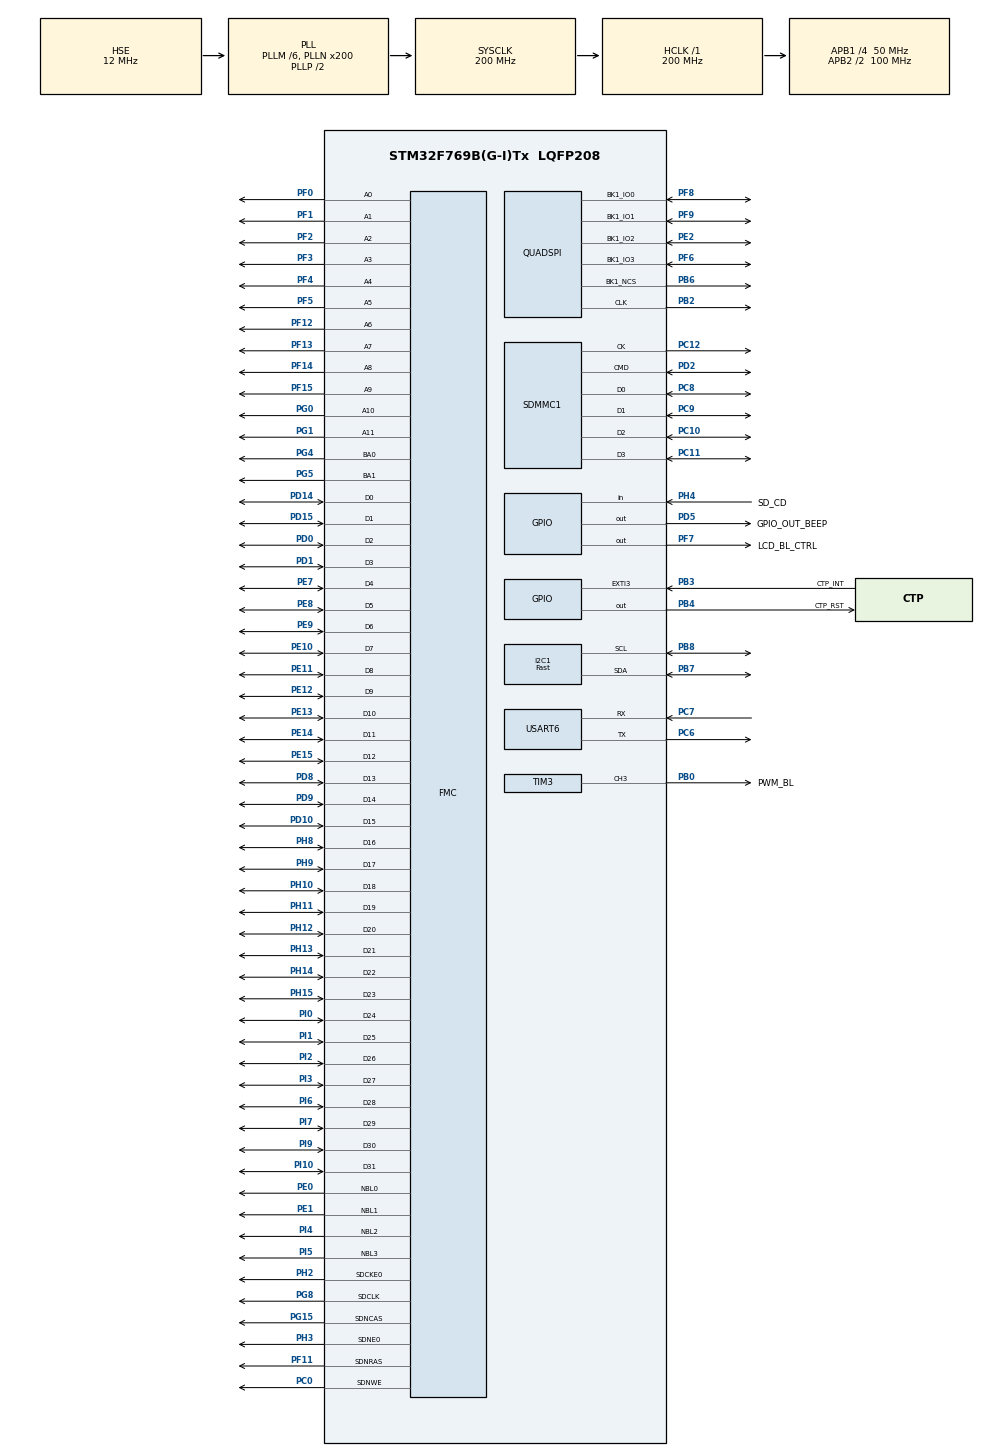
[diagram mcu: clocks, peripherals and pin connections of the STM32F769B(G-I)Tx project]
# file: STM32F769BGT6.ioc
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CORTEX_M7.ART_ACCELERATOR_ENABLE=1
CORTEX_M7.AccessPermission-Cortex_Memory_Protection_Unit_Region0_Settings=MPU_REGION_FULL_ACCESS
CORTEX_M7.AccessPermission-Cortex_Memory_Protection_Unit_Region2_Settings=MPU_REGION_PRIV_RO
CORTEX_M7.AccessPermission_S-Cortex_Memory_Protection_Unit_Region2_Settings_S=MPU_REGION_PRIV_RO
CORTEX_M7.AccessPermission_S-Cortex_Memory_Protection_Unit_Region3_Settings_S=MPU_REGION_FULL_ACCESS
CORTEX_M7.AccessPermission_Spec=MPU_REGION_FULL_ACCESS
CORTEX_M7.BaseAddress-Cortex_Memory_Protection_Unit_Region0_Settings=0xC0000000
CORTEX_M7.BaseAddress-Cortex_Memory_Protection_Unit_Region1_Settings=0x90000000
CORTEX_M7.BaseAddress-Cortex_Memory_Protection_Unit_Region2_Settings=0x90000000
CORTEX_M7.BaseAddress_S-Cortex_Memory_Protection_Unit_Region1_Settings_S=0x90000000
CORTEX_M7.BaseAddress_S-Cortex_Memory_Protection_Unit_Region2_Settings_S=0x90000000
CORTEX_M7.BaseAddress_S-Cortex_Memory_Protection_Unit_Region3_Settings_S=0xC0000000
CORTEX_M7.BaseAddress_Spec=0x20000000
CORTEX_M7.CPU_DCache=Enabled
CORTEX_M7.CPU_ICache=Enabled
CORTEX_M7.DisableExec-Cortex_Memory_Protection_Unit_Region1_Settings=MPU_INSTRUCTION_ACCESS_DISABLE
CORTEX_M7.DisableExec-Cortex_Memory_Protection_Unit_Region2_Settings=MPU_INSTRUCTION_ACCESS_DISABLE
CORTEX_M7.DisableExec_S-Cortex_Memory_Protection_Unit_Region1_Settings_S=MPU_INSTRUCTION_ACCESS_DISABLE
CORTEX_M7.DisableExec_S-Cortex_Memory_Protection_Unit_Region2_Settings_S=MPU_INSTRUCTION_ACCESS_DISABLE
CORTEX_M7.DisableExec_S-Cortex_Memory_Protection_Unit_Region3_Settings_S=MPU_INSTRUCTION_ACCESS_DISABLE
CORTEX_M7.Enable-Cortex_Memory_Protection_Unit_Region0_Settings=MPU_REGION_ENABLE
CORTEX_M7.Enable-Cortex_Memory_Protection_Unit_Region1_Settings=MPU_REGION_ENABLE
CORTEX_M7.Enable-Cortex_Memory_Protection_Unit_Region2_Settings=MPU_REGION_ENABLE
CORTEX_M7.Enable_S-Cortex_Memory_Protection_Unit_Region1_Settings_S=MPU_REGION_ENABLE
CORTEX_M7.Enable_S-Cortex_Memory_Protection_Unit_Region2_Settings_S=MPU_REGION_ENABLE
CORTEX_M7.Enable_S-Cortex_Memory_Protection_Unit_Region3_Settings_S=MPU_REGION_ENABLE
CORTEX_M7.IsBufferable_S-Cortex_Memory_Protection_Unit_Region3_Settings_S=MPU_ACCESS_BUFFERABLE
CORTEX_M7.IsBufferable_Spec=MPU_ACCESS_BUFFERABLE
CORTEX_M7.IsCacheable-Cortex_Memory_Protection_Unit_Region0_Settings=MPU_ACCESS_CACHEABLE
CORTEX_M7.IsCacheable-Cortex_Memory_Protection_Unit_Region2_Settings=MPU_ACCESS_CACHEABLE
CORTEX_M7.IsCacheable_S-Cortex_Memory_Protection_Unit_Region2_Settings_S=MPU_ACCESS_CACHEABLE
CORTEX_M7.IsCacheable_S-Cortex_Memory_Protection_Unit_Region3_Settings_S=MPU_ACCESS_CACHEABLE
CORTEX_M7.IsCacheable_Spec=MPU_ACCESS_CACHEABLE
CORTEX_M7.IsShareable-Cortex_Memory_Protection_Unit_Region0_Settings=MPU_ACCESS_SHAREABLE
CORTEX_M7.IsShareable_S-Cortex_Memory_Protection_Unit_Region3_Settings_S=MPU_ACCESS_NOT_SHAREABLE
CORTEX_M7.IsShareable_Spec=MPU_ACCESS_NOT_SHAREABLE
CORTEX_M7.MPU_Control=MPU_PRIVILEGED_DEFAULT
CORTEX_M7.Size-Cortex_Memory_Protection_Unit_Region0_Settings=MPU_REGION_SIZE_16MB
CORTEX_M7.Size-Cortex_Memory_Protection_Unit_Region1_Settings=MPU_REGION_SIZE_256MB
CORTEX_M7.Size-Cortex_Memory_Protection_Unit_Region2_Settings=MPU_REGION_SIZE_16MB
CORTEX_M7.Size_S-Cortex_Memory_Protection_Unit_Region1_Settings_S=MPU_REGION_SIZE_256MB
CORTEX_M7.Size_S-Cortex_Memory_Protection_Unit_Region2_Settings_S=MPU_REGION_SIZE_16MB
CORTEX_M7.Size_S-Cortex_Memory_Protection_Unit_Region3_Settings_S=MPU_REGION_SIZE_16MB
CORTEX_M7.Size_Spec=MPU_REGION_SIZE_512KB
CORTEX_M7.SubRegionDisable_Spec=0
CORTEX_M7.default_mode_Activation=0
DMA2D.ColorMode=DMA2D_OUTPUT_RGB565
DSIHOST.BTA_FlowControl=__NULL
DSIHOST.FrameBTAAcknowledgeEnable=DSI_FBTAA_ENABLE
DSIHOST.GCEIE=HAL_DSI_ERROR_NONE
DSIHOST.LPCommandEnable=DSI_LP_COMMAND_ENABLE
DSIHOST.LPHorizontalBackPorchEnable=DSI_LP_HBP_ENABLE
DSIHOST.LPHorizontalFrontPorchEnable=DSI_LP_HFP_ENABLE
DSIHOST.LPLargestPacketSize=16
DSIHOST.LPVACTLargestPacketSize=0
DSIHOST.LPVerticalActiveEnable=DSI_LP_VACT_ENABLE
DSIHOST.LPVerticalBackPorchEnable=DSI_LP_VBP_ENABLE
DSIHOST.LPVerticalFrontPorchEnable=DSI_LP_VFP_ENABLE
DSIHOST.LPVerticalSyncActiveEnable=DSI_LP_VSYNC_ENABLE
DSIHOST.LPWREIE=HAL_DSI_ERROR_OVF
DSIHOST.Mode=DSI_VID_MODE_BURST
DSIHOST.NumberOfLanes=DSI_TWO_DATA_LANES
DSIHOST.State_SDD=__NULL
DSIHOST.StopWaitTime=0
DSIHOST_CKN.Mode=DSIHost_Video
DSIHOST_CKN.Signal=DSIHOST_CKN
DSIHOST_CKP.Mode=DSIHost_Video
DSIHOST_CKP.Signal=DSIHOST_CKP
DSIHOST_D0N.Mode=DSIHost_Video
DSIHOST_D0N.Signal=DSIHOST_D0N
DSIHOST_D0P.Mode=DSIHost_Video
DSIHOST_D0P.Signal=DSIHOST_D0P
DSIHOST_D1N.Mode=DSIHost_Video
DSIHOST_D1N.Signal=DSIHOST_D1N
DSIHOST_D1P.Mode=DSIHost_Video
DSIHOST_D1P.Signal=DSIHOST_D1P
Dma.Request0=SDMMC1_RX
Dma.Request1=SDMMC1_TX
Dma.SDMMC1_RX.0.Direction=DMA_PERIPH_TO_MEMORY
Dma.SDMMC1_RX.0.FIFOMode=DMA_FIFOMODE_ENABLE
Dma.SDMMC1_RX.0.FIFOThreshold=DMA_FIFO_THRESHOLD_FULL
Dma.SDMMC1_RX.0.Instance=DMA2_Stream3
Dma.SDMMC1_RX.0.MemBurst=DMA_MBURST_INC4
Dma.SDMMC1_RX.0.MemDataAlignment=DMA_MDATAALIGN_WORD
Dma.SDMMC1_RX.0.MemInc=DMA_MINC_ENABLE
Dma.SDMMC1_RX.0.Mode=DMA_PFCTRL
Dma.SDMMC1_RX.0.PeriphBurst=DMA_PBURST_INC4
Dma.SDMMC1_RX.0.PeriphDataAlignment=DMA_PDATAALIGN_WORD
Dma.SDMMC1_RX.0.PeriphInc=DMA_PINC_DISABLE
Dma.SDMMC1_RX.0.Priority=DMA_PRIORITY_LOW
Dma.SDMMC1_TX.1.Direction=DMA_MEMORY_TO_PERIPH
Dma.SDMMC1_TX.1.FIFOMode=DMA_FIFOMODE_ENABLE
Dma.SDMMC1_TX.1.FIFOThreshold=DMA_FIFO_THRESHOLD_FULL
Dma.SDMMC1_TX.1.Instance=DMA2_Stream6
Dma.SDMMC1_TX.1.MemBurst=DMA_MBURST_INC4
Dma.SDMMC1_TX.1.MemDataAlignment=DMA_MDATAALIGN_WORD
Dma.SDMMC1_TX.1.MemInc=DMA_MINC_ENABLE
Dma.SDMMC1_TX.1.Mode=DMA_PFCTRL
Dma.SDMMC1_TX.1.PeriphBurst=DMA_PBURST_INC4
Dma.SDMMC1_TX.1.PeriphDataAlignment=DMA_PDATAALIGN_WORD
Dma.SDMMC1_TX.1.PeriphInc=DMA_PINC_DISABLE
Dma.SDMMC1_TX.1.Priority=DMA_PRIORITY_LOW
FATFS.BSP.number=1
FATFS._CODE_PAGE=950
FATFS._FS_EXFAT=1
FATFS._USE_LFN=2
FATFS0.BSP.STBoard=false
FATFS0.BSP.api=Unknown
FATFS0.BSP.instance=PH4
FATFS0.BSP.ip=GPIO
FATFS0.BSP.mode=Input
FATFS0.BSP.name=Detect_SDIO
FATFS0.BSP.solution=PH4
FMC.CASLatency1=FMC_SDRAM_CAS_LATENCY_2
FMC.ExitSelfRefreshDelay1=8
FMC.LoadToActiveDelay1=2
FMC.RCDDelay1=2
FMC.RPDelay1=2
FMC.ReadBurst1=FMC_SDRAM_RBURST_ENABLE
FMC.RowCycleDelay1=6
FMC.RowCycleDelay2=6
FMC.SDClockPeriod1=FMC_SDRAM_CLOCK_PERIOD_2
FMC.SelfRefreshTime1=5
FMC.WriteRecoveryTime1=4
FREERTOS.Tasks01=display_debug,24,500,display_debugTask,Default,NULL,Dynamic,NULL,NULL;TouchgfxTask,24,4096,StartTouchgfxTask,Default,NULL,Dynamic,NULL,NULL
FREERTOS.configENABLE_FPU=1
FREERTOS.configTOTAL_HEAP_SIZE=80000
FREERTOS.configUSE_IDLE_HOOK=1
FREERTOS.configUSE_NEWLIB_REENTRANT=1
I2C1.I2C_Speed_Mode=I2C_Fast
I2C1.Timing=0x109035B7
LTDC.ActiveH=1424
LTDC.ActiveW=280
LTDC.Alpha_L0=255
LTDC.BlendingFactor1_L0=LTDC_BLENDING_FACTOR1_CA
LTDC.BlendingFactor2_L0=LTDC_BLENDING_FACTOR2_CA
LTDC.Blue_L0=255
LTDC.FBStartAdress_L0=0xC0000000
LTDC.Green_L0=255
LTDC.HBP=40
LTDC.HFP=150
LTDC.HSync=24
LTDC.ImageHeight_L0=1424
LTDC.ImageWidth_L0=280
LTDC.Layers=0
LTDC.PixelFormat_L0=LTDC_PIXEL_FORMAT_RGB565
LTDC.Red_L0=255
LTDC.VBP=10
LTDC.VFP=12
LTDC.VSync=6
LTDC.WindowX1_L0=280
LTDC.WindowY1_L0=1424
Mcu.Family=STM32F7
Mcu.Name=STM32F769B(G-I)Tx
Mcu.Package=LQFP208
NVIC.DMA2D_IRQn=true\:5\:0\:false\:false\:true\:true\:true\:true\:true
NVIC.DMA2_Stream3_IRQn=true\:5\:0\:false\:false\:true\:true\:false\:true\:true
NVIC.DMA2_Stream6_IRQn=true\:5\:0\:false\:false\:true\:true\:false\:true\:true
NVIC.EXTI3_IRQn=true\:5\:0\:false\:false\:true\:true\:true\:true\:true
NVIC.I2C1_ER_IRQn=true\:5\:0\:false\:false\:true\:true\:true\:true\:true
NVIC.I2C1_EV_IRQn=true\:5\:0\:false\:false\:true\:true\:true\:true\:true
NVIC.LTDC_IRQn=true\:5\:0\:false\:false\:true\:true\:true\:true\:true
NVIC.PriorityGroup=NVIC_PRIORITYGROUP_4
NVIC.SDMMC1_IRQn=true\:5\:0\:false\:false\:true\:true\:true\:true\:true
NVIC.TIM6_DAC_IRQn=true\:0\:0\:true\:false\:true\:false\:false\:true\:true
NVIC.TimeBase=TIM6_DAC_IRQn
NVIC.TimeBaseIP=TIM6
NVIC.USART6_IRQn=true\:5\:0\:false\:false\:true\:true\:true\:true\:true
PA13.Mode=Serial_Wire
PA13.Signal=SYS_JTMS-SWDIO
PA14.Mode=Serial_Wire
PA14.Signal=SYS_JTCK-SWCLK
PB0.GPIO_Label=PWM_BL
PB0.Signal=S_TIM3_CH3
PB2.Mode=Single Bank 1
PB2.Signal=QUADSPI_CLK
PB3.GPIO_Label=CTP_INT
PB3.GPIO_ModeDefaultEXTI=GPIO_MODE_IT_FALLING
PB3.Signal=GPXTI3
PB4.GPIO_Label=CTP_RST
PB4.Signal=GPIO_Output
PB6.Mode=Single Bank 1
PB6.Signal=QUADSPI_BK1_NCS
PB7.GPIO_Pu=GPIO_PULLUP
PB7.Mode=I2C
PB7.Signal=I2C1_SDA
PB8.GPIO_Pu=GPIO_PULLUP
PB8.Mode=I2C
PB8.Signal=I2C1_SCL
PC0.Signal=FMC_SDNWE
PC10.Mode=SD_4_bits_Wide_bus
PC10.Signal=SDMMC1_D2
PC11.Mode=SD_4_bits_Wide_bus
PC11.Signal=SDMMC1_D3
PC12.Mode=SD_4_bits_Wide_bus
PC12.Signal=SDMMC1_CK
PC14/OSC32_IN.Mode=LSE-External-Oscillator
PC14/OSC32_IN.Signal=RCC_OSC32_IN
PC15/OSC32_OUT.Mode=LSE-External-Oscillator
PC15/OSC32_OUT.Signal=RCC_OSC32_OUT
PC6.Mode=Asynchronous
PC6.Signal=USART6_TX
PC7.Mode=Asynchronous
PC7.Signal=USART6_RX
PC8.Mode=SD_4_bits_Wide_bus
PC8.Signal=SDMMC1_D0
PC9.Mode=SD_4_bits_Wide_bus
PC9.Signal=SDMMC1_D1
PD0.Signal=FMC_D2_DA2
PD1.Signal=FMC_D3_DA3
PD10.Signal=FMC_D15_DA15
PD14.Signal=FMC_D0_DA0
PD15.Signal=FMC_D1_DA1
PD2.Mode=SD_4_bits_Wide_bus
PD2.Signal=SDMMC1_CMD
PD5.GPIO_Label=GPIO_OUT_BEEP
PD5.GPIO_Speed=GPIO_SPEED_FREQ_VERY_HIGH
PD5.Signal=GPIO_Output
PD8.Signal=FMC_D13_DA13
PD9.Signal=FMC_D14_DA14
PE0.Signal=FMC_NBL0
PE1.Signal=FMC_NBL1
PE10.Signal=FMC_D7_DA7
PE11.Signal=FMC_D8_DA8
PE12.Signal=FMC_D9_DA9
PE13.Signal=FMC_D10_DA10
PE14.Signal=FMC_D11_DA11
PE15.Signal=FMC_D12_DA12
PE2.Mode=Single Bank 1
PE2.Signal=QUADSPI_BK1_IO2
PE7.Signal=FMC_D4_DA4
PE8.Signal=FMC_D5_DA5
PE9.Signal=FMC_D6_DA6
PF0.Signal=FMC_A0
PF1.Signal=FMC_A1
PF11.Signal=FMC_SDNRAS
PF12.Signal=FMC_A6
PF13.Signal=FMC_A7
PF14.Signal=FMC_A8
PF15.Signal=FMC_A9
PF2.Signal=FMC_A2
PF3.Signal=FMC_A3
PF4.Signal=FMC_A4
PF5.Signal=FMC_A5
PF6.Mode=Single Bank 1
PF6.Signal=QUADSPI_BK1_IO3
PF7.GPIO_Label=LCD_BL_CTRL
PF7.GPIO_Speed=GPIO_SPEED_FREQ_VERY_HIGH
PF7.Signal=GPIO_Output
PF8.Mode=Single Bank 1
PF8.Signal=QUADSPI_BK1_IO0
PF9.Mode=Single Bank 1
PF9.Signal=QUADSPI_BK1_IO1
PG0.Signal=FMC_A10
PG1.Signal=FMC_A11
PG15.Signal=FMC_SDNCAS
PG4.Signal=FMC_A14_BA0
PG5.Signal=FMC_A15_BA1
PG8.Signal=FMC_SDCLK
PH0/OSC_IN.Mode=HSE-External-Oscillator
PH0/OSC_IN.Signal=RCC_OSC_IN
PH1/OSC_OUT.Mode=HSE-External-Oscillator
PH1/OSC_OUT.Signal=RCC_OSC_OUT
PH10.Signal=FMC_D18
PH11.Signal=FMC_D19
PH12.Signal=FMC_D20
PH13.Signal=FMC_D21
PH14.Signal=FMC_D22
PH15.Signal=FMC_D23
PH2.Mode=SdramChipSelect1_1
PH2.Signal=FMC_SDCKE0
PH3.Mode=SdramChipSelect1_1
PH3.Signal=FMC_SDNE0
PH4.GPIO_Label=SD_CD
PH4.Signal=GPIO_Input
PH8.Signal=FMC_D16
PH9.Signal=FMC_D17
PI0.Signal=FMC_D24
PI1.Signal=FMC_D25
PI10.Signal=FMC_D31
PI2.Signal=FMC_D26
PI3.Signal=FMC_D27
PI4.Signal=FMC_NBL2
PI5.Signal=FMC_NBL3
PI6.Signal=FMC_D28
PI7.Signal=FMC_D29
PI9.Signal=FMC_D30
ProjectManager.HeapSize=0x1000
ProjectManager.StackSize=0x1000
ProjectManager.TargetToolchain=STM32CubeIDE
QUADSPI.ChipSelectHighTime=QSPI_CS_HIGH_TIME_2_CYCLE
QUADSPI.ClockPrescaler=2
QUADSPI.FifoThreshold=4
QUADSPI.FlashSize=23
QUADSPI.SampleShifting=QSPI_SAMPLE_SHIFTING_HALFCYCLE
RCC.AHBFreq_Value=200000000
RCC.APB1CLKDivider=RCC_HCLK_DIV4
RCC.APB1Freq_Value=50000000
RCC.APB1TimFreq_Value=100000000
RCC.APB2CLKDivider=RCC_HCLK_DIV2
RCC.APB2Freq_Value=100000000
RCC.APB2TimFreq_Value=200000000
RCC.CortexFreq_Value=200000000
RCC.HCLKFreq_Value=200000000
RCC.HSE_VALUE=12000000
RCC.HSI_VALUE=16000000
RCC.I2C1CLockSelection=RCC_I2C1CLKSOURCE_SYSCLK
RCC.LSE_Drive_Capability=RCC_LSEDRIVE_HIGH
RCC.PLLDSIIDF=DSI_PLL_IN_DIV3
RCC.PLLDSINDIV=125
RCC.PLLM=6
RCC.PLLN=200
RCC.PLLQ=8
RCC.PLLR=7
RCC.PLLSAIN=120
RCC.PLLSAIR=3
RCC.PLLSourceVirtual=RCC_PLLSOURCE_HSE
RCC.PWR_Regulator_Voltage_Scale=PWR_REGULATOR_VOLTAGE_SCALE1
RCC.RTCClockSelection=RCC_RTCCLKSOURCE_LSE
RCC.SDMMCClockSelection=RCC_SDMMC1CLKSOURCE_CLK48
RCC.SYSCLKFreq_VALUE=200000000
RCC.SYSCLKSource=RCC_SYSCLKSOURCE_PLLCLK
RCC.USART6CLockSelection=RCC_USART6CLKSOURCE_SYSCLK
RCC.USBFreq_Value=50000000
RCC.VCOOutputFreq_Value=400000000
RTC.Format=RTC_FORMAT_BIN
RTC.Year=24
SH.FMC_A0.0=FMC_A0,12b-sda1
SH.FMC_A1.0=FMC_A1,12b-sda1
SH.FMC_A10.0=FMC_A10,12b-sda1
SH.FMC_A11.0=FMC_A11,12b-sda1
SH.FMC_A14_BA0.0=FMC_BA0,FourSdramBanks1
SH.FMC_A15_BA1.0=FMC_BA1,FourSdramBanks1
SH.FMC_A2.0=FMC_A2,12b-sda1
SH.FMC_A3.0=FMC_A3,12b-sda1
SH.FMC_A4.0=FMC_A4,12b-sda1
SH.FMC_A5.0=FMC_A5,12b-sda1
SH.FMC_A6.0=FMC_A6,12b-sda1
SH.FMC_A7.0=FMC_A7,12b-sda1
SH.FMC_A8.0=FMC_A8,12b-sda1
SH.FMC_A9.0=FMC_A9,12b-sda1
SH.FMC_D0_DA0.0=FMC_D0,sd-32b-d1
SH.FMC_D10_DA10.0=FMC_D10,sd-32b-d1
SH.FMC_D11_DA11.0=FMC_D11,sd-32b-d1
SH.FMC_D12_DA12.0=FMC_D12,sd-32b-d1
SH.FMC_D13_DA13.0=FMC_D13,sd-32b-d1
SH.FMC_D14_DA14.0=FMC_D14,sd-32b-d1
SH.FMC_D15_DA15.0=FMC_D15,sd-32b-d1
SH.FMC_D16.0=FMC_D16,sd-32b-d1
SH.FMC_D17.0=FMC_D17,sd-32b-d1
SH.FMC_D18.0=FMC_D18,sd-32b-d1
SH.FMC_D19.0=FMC_D19,sd-32b-d1
SH.FMC_D1_DA1.0=FMC_D1,sd-32b-d1
SH.FMC_D20.0=FMC_D20,sd-32b-d1
SH.FMC_D21.0=FMC_D21,sd-32b-d1
SH.FMC_D22.0=FMC_D22,sd-32b-d1
SH.FMC_D23.0=FMC_D23,sd-32b-d1
SH.FMC_D24.0=FMC_D24,sd-32b-d1
SH.FMC_D25.0=FMC_D25,sd-32b-d1
SH.FMC_D26.0=FMC_D26,sd-32b-d1
SH.FMC_D27.0=FMC_D27,sd-32b-d1
SH.FMC_D28.0=FMC_D28,sd-32b-d1
SH.FMC_D29.0=FMC_D29,sd-32b-d1
SH.FMC_D2_DA2.0=FMC_D2,sd-32b-d1
SH.FMC_D30.0=FMC_D30,sd-32b-d1
SH.FMC_D31.0=FMC_D31,sd-32b-d1
SH.FMC_D3_DA3.0=FMC_D3,sd-32b-d1
SH.FMC_D4_DA4.0=FMC_D4,sd-32b-d1
SH.FMC_D5_DA5.0=FMC_D5,sd-32b-d1
SH.FMC_D6_DA6.0=FMC_D6,sd-32b-d1
SH.FMC_D7_DA7.0=FMC_D7,sd-32b-d1
SH.FMC_D8_DA8.0=FMC_D8,sd-32b-d1
SH.FMC_D9_DA9.0=FMC_D9,sd-32b-d1
SH.FMC_NBL0.0=FMC_NBL0,Sd4ByteEnable1
SH.FMC_NBL1.0=FMC_NBL1,Sd4ByteEnable1
SH.FMC_NBL2.0=FMC_NBL2,Sd4ByteEnable1
SH.FMC_NBL3.0=FMC_NBL3,Sd4ByteEnable1
SH.FMC_SDCLK.0=FMC_SDCLK,12b-sda1
SH.FMC_SDNCAS.0=FMC_SDNCAS,12b-sda1
SH.FMC_SDNRAS.0=FMC_SDNRAS,12b-sda1
SH.FMC_SDNWE.0=FMC_SDNWE,12b-sda1
SH.S_TIM3_CH3.0=TIM3_CH3,PWM Generation3 CH3
STMicroelectronics.X-CUBE-TOUCHGFX.4.18.1.ApplicationCcGraphicsJjApplication=TouchGFXOoGenerator
STMicroelectronics.X-CUBE-TOUCHGFX.4.18.1.tgfx_buffering_strategy=Double
STMicroelectronics.X-CUBE-TOUCHGFX.4.18.1.tgfx_custom_height=1424
STMicroelectronics.X-CUBE-TOUCHGFX.4.18.1.tgfx_display_interface=disp_ltdc
STMicroelectronics.X-CUBE-TOUCHGFX.4.18.1.tgfx_hardware_accelerator=dma_2d
STMicroelectronics.X-CUBE-TOUCHGFX.4.18.1.tgfx_pixel_format=RGB565\:16
STMicroelectronics.X-CUBE-TOUCHGFX.4.18.1.tgfx_vsync=vsync_ltdc
STMicroelectronics.X-CUBE-TOUCHGFX.4.18.1_IsPackSelfContextualization=true
TIM3.Channel-PWM\ Generation3\ CH3=TIM_CHANNEL_3
TIM3.OCPolarity_3=TIM_OCPOLARITY_LOW
TIM3.Period=100-1
TIM3.Prescaler=100-1
USART6.VirtualMode-Asynchronous=VM_ASYNC
VP_CRC_VS_CRC.Mode=CRC_Activate
VP_DMA2D_VS_DMA2D.Mode=DMA2D_Activate
VP_FATFS_VS_SDIO.Mode=SDIO
VP_FREERTOS_VS_CMSIS_V2.Mode=CMSIS_V2
VP_LTDC_DSIMode.Mode=RGB565
VP_RTC_VS_RTC_Activate.Mode=RTC_Enabled
VP_RTC_VS_RTC_Calendar.Mode=RTC_Calendar
VP_STMicroelectronics.X-CUBE-TOUCHGFX_VS_GraphicsJjApplication_4.18.1.Mode=GraphicsJjApplication
VP_SYS_VS_tim6.Mode=TIM6
VP_TIM3_VS_ClockSourceINT.Mode=Internal
board=custom

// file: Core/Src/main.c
/* USER CODE BEGIN Header */
/**
  ******************************************************************************
  * @file           : main.c
  * @brief          : Main program body
  ******************************************************************************
  * @attention
  *
  * Copyright (c) 2024 STMicroelectronics.
  * All rights reserved.
  *
  * This software is licensed under terms that can be found in the LICENSE file
  * in the root directory of this software component.
  * If no LICENSE file comes with this software, it is provided AS-IS.
  *
  ******************************************************************************
  */
/* USER CODE END Header */
#include "main.h"
#include "cmsis_os.h"
#include "fatfs.h"
#include "app_touchgfx.h"

/* USER CODE BEGIN Includes */
#include <string.h>
#include <ExFlash.h>
#include <ota7290n.h>
#include "ExHardware.h"
/* USER CODE END Includes */

/* USER CODE BEGIN PM */
#define LAYER0_ADDRESS               ((uint32_t)0xC0000000)

extern uint8_t pucByte;

Touch_t Touch;
/* USER CODE END PM */

CRC_HandleTypeDef hcrc;

DMA2D_HandleTypeDef hdma2d;

DSI_HandleTypeDef hdsi;

I2C_HandleTypeDef hi2c1;

LTDC_HandleTypeDef hltdc;

QSPI_HandleTypeDef hqspi;

RTC_HandleTypeDef hrtc;

SD_HandleTypeDef hsd1;
DMA_HandleTypeDef hdma_sdmmc1_rx;
DMA_HandleTypeDef hdma_sdmmc1_tx;

TIM_HandleTypeDef htim3;

UART_HandleTypeDef huart6;

SDRAM_HandleTypeDef hsdram1;

/* Definitions for display_debug */
osThreadId_t display_debugHandle;
const osThreadAttr_t display_debug_attributes = {
  .name = "display_debug",
  .stack_size = 500 * 4,
  .priority = (osPriority_t) osPriorityNormal,
};
/* Definitions for TouchgfxTask */
osThreadId_t TouchgfxTaskHandle;
const osThreadAttr_t TouchgfxTask_attributes = {
  .name = "TouchgfxTask",
  .stack_size = 4096 * 4,
  .priority = (osPriority_t) osPriorityNormal,
};

void SystemClock_Config(void);
static void MPU_Config(void);
static void MX_GPIO_Init(void);
static void MX_DMA2D_Init(void);
static void MX_FMC_Init(void);
static void MX_LTDC_Init(void);
static void MX_QUADSPI_Init(void);
static void MX_CRC_Init(void);
static void MX_DSIHOST_DSI_Init(void);
static void MX_TIM3_Init(void);
static void MX_I2C1_Init(void);
static void MX_SDMMC1_SD_Init(void);
static void MX_DMA_Init(void);
static void MX_USART6_UART_Init(void);
static void MX_RTC_Init(void);
void display_debugTask(void *argument);
void StartTouchgfxTask(void *argument);

/* USER CODE BEGIN PFP */
static void MX_SDRAM_InitEx ( void );
/* USER CODE END PFP */

int main(void)
{

  /* MPU Configuration--------------------------------------------------------*/
  MPU_Config();

  /* Enable I-Cache---------------------------------------------------------*/
  SCB_EnableICache();

  /* Enable D-Cache---------------------------------------------------------*/
  SCB_EnableDCache();

  /* MCU Configuration--------------------------------------------------------*/

  /* Reset of all peripherals, Initializes the Flash interface and the Systick. */
  HAL_Init();

  /* Configure the system clock */
  SystemClock_Config();

  /* Initialize all configured peripherals */
  MX_GPIO_Init();
  MX_DMA2D_Init();
  MX_FMC_Init();
  MX_LTDC_Init();
  MX_QUADSPI_Init();
  MX_CRC_Init();
  MX_DSIHOST_DSI_Init();
  MX_TIM3_Init();
  MX_I2C1_Init();
  MX_SDMMC1_SD_Init();
  MX_DMA_Init();
  MX_FATFS_Init();
  MX_USART6_UART_Init();
  MX_RTC_Init();
  MX_TouchGFX_Init();
  /* USER CODE BEGIN 2 */
  HAL_DSI_Start(&hdsi);

  OTA7290N_Init();

  memset((void *)0xC0000000, 0x00, 280*1424*2*2); //RESET

  HAL_LTDC_ProgramLineEvent(&hltdc, 0);

  HAL_UART_Receive_IT(&huart6, &pucByte, 1);

  HAL_GPIO_WritePin( GPIO_OUT_BEEP_GPIO_Port, GPIO_OUT_BEEP_Pin, GPIO_PIN_SET );
  HAL_Delay(100);
  HAL_GPIO_WritePin( GPIO_OUT_BEEP_GPIO_Port, GPIO_OUT_BEEP_Pin, GPIO_PIN_RESET );

  /* USER CODE END 2 */

  /* Init scheduler */
  osKernelInitialize();

  /* Create the thread(s) */
  /* creation of display_debug */
  display_debugHandle = osThreadNew(display_debugTask, NULL, &display_debug_attributes);

  /* creation of TouchgfxTask */
  TouchgfxTaskHandle = osThreadNew(StartTouchgfxTask, NULL, &TouchgfxTask_attributes);

  /* Start scheduler */
  osKernelStart();

  /* We should never get here as control is now taken by the scheduler */
  /* Infinite loop */
  while (1)
  {

  }
}

void SystemClock_Config(void)
{
  RCC_OscInitTypeDef RCC_OscInitStruct = {0};
  RCC_ClkInitTypeDef RCC_ClkInitStruct = {0};

  /** Configure LSE Drive Capability
  */
  HAL_PWR_EnableBkUpAccess();
  __HAL_RCC_LSEDRIVE_CONFIG(RCC_LSEDRIVE_HIGH);

  /** Configure the main internal regulator output voltage
  */
  __HAL_RCC_PWR_CLK_ENABLE();
  __HAL_PWR_VOLTAGESCALING_CONFIG(PWR_REGULATOR_VOLTAGE_SCALE1);

  /** Initializes the RCC Oscillators according to the specified parameters
  * in the RCC_OscInitTypeDef structure.
  */
  RCC_OscInitStruct.OscillatorType = RCC_OSCILLATORTYPE_HSE|RCC_OSCILLATORTYPE_LSE;
  RCC_OscInitStruct.HSEState = RCC_HSE_ON;
  RCC_OscInitStruct.LSEState = RCC_LSE_ON;
  RCC_OscInitStruct.PLL.PLLState = RCC_PLL_ON;
  RCC_OscInitStruct.PLL.PLLSource = RCC_PLLSOURCE_HSE;
  RCC_OscInitStruct.PLL.PLLM = 6;
  RCC_OscInitStruct.PLL.PLLN = 200;
  RCC_OscInitStruct.PLL.PLLP = RCC_PLLP_DIV2;
  RCC_OscInitStruct.PLL.PLLQ = 8;
  RCC_OscInitStruct.PLL.PLLR = 7;
  if (HAL_RCC_OscConfig(&RCC_OscInitStruct) != HAL_OK)
  {
    Error_Handler();
  }

  /** Activate the Over-Drive mode
  */
  if (HAL_PWREx_EnableOverDrive() != HAL_OK)
  {
    Error_Handler();
  }

  /** Initializes the CPU, AHB and APB buses clocks
  */
  RCC_ClkInitStruct.ClockType = RCC_CLOCKTYPE_HCLK|RCC_CLOCKTYPE_SYSCLK
                              |RCC_CLOCKTYPE_PCLK1|RCC_CLOCKTYPE_PCLK2;
  RCC_ClkInitStruct.SYSCLKSource = RCC_SYSCLKSOURCE_PLLCLK;
  RCC_ClkInitStruct.AHBCLKDivider = RCC_SYSCLK_DIV1;
  RCC_ClkInitStruct.APB1CLKDivider = RCC_HCLK_DIV4;
  RCC_ClkInitStruct.APB2CLKDivider = RCC_HCLK_DIV2;

  if (HAL_RCC_ClockConfig(&RCC_ClkInitStruct, FLASH_LATENCY_6) != HAL_OK)
  {
    Error_Handler();
  }
}

static void MX_CRC_Init(void)
{

  hcrc.Instance = CRC;
  hcrc.Init.DefaultPolynomialUse = DEFAULT_POLYNOMIAL_ENABLE;
  hcrc.Init.DefaultInitValueUse = DEFAULT_INIT_VALUE_ENABLE;
  hcrc.Init.InputDataInversionMode = CRC_INPUTDATA_INVERSION_NONE;
  hcrc.Init.OutputDataInversionMode = CRC_OUTPUTDATA_INVERSION_DISABLE;
  hcrc.InputDataFormat = CRC_INPUTDATA_FORMAT_BYTES;
  if (HAL_CRC_Init(&hcrc) != HAL_OK)
  {
    Error_Handler();
  }

}

static void MX_DMA2D_Init(void)
{

  hdma2d.Instance = DMA2D;
  hdma2d.Init.Mode = DMA2D_M2M;
  hdma2d.Init.ColorMode = DMA2D_OUTPUT_RGB565;
  hdma2d.Init.OutputOffset = 0;
  hdma2d.LayerCfg[1].InputOffset = 0;
  hdma2d.LayerCfg[1].InputColorMode = DMA2D_INPUT_RGB565;
  hdma2d.LayerCfg[1].AlphaMode = DMA2D_NO_MODIF_ALPHA;
  hdma2d.LayerCfg[1].InputAlpha = 0;
  hdma2d.LayerCfg[1].AlphaInverted = DMA2D_REGULAR_ALPHA;
  hdma2d.LayerCfg[1].RedBlueSwap = DMA2D_RB_REGULAR;
  if (HAL_DMA2D_Init(&hdma2d) != HAL_OK)
  {
    Error_Handler();
  }
  if (HAL_DMA2D_ConfigLayer(&hdma2d, 1) != HAL_OK)
  {
    Error_Handler();
  }

}

static void MX_DSIHOST_DSI_Init(void)
{

  DSI_PLLInitTypeDef PLLInit = {0};
  DSI_HOST_TimeoutTypeDef HostTimeouts = {0};
  DSI_PHY_TimerTypeDef PhyTimings = {0};
  DSI_VidCfgTypeDef VidCfg = {0};

  /* USER CODE BEGIN DSIHOST_Init 1 */
  hdsi.Instance = DSI;

  HAL_DSI_DeInit( &hdsi );

  /* USER CODE END DSIHOST_Init 1 */
  hdsi.Instance = DSI;
  hdsi.Init.AutomaticClockLaneControl = DSI_AUTO_CLK_LANE_CTRL_DISABLE;
  hdsi.Init.TXEscapeCkdiv = 4;
  hdsi.Init.NumberOfLanes = DSI_TWO_DATA_LANES;
  PLLInit.PLLNDIV = 125;
  PLLInit.PLLIDF = DSI_PLL_IN_DIV3;
  PLLInit.PLLODF = DSI_PLL_OUT_DIV1;
  if (HAL_DSI_Init(&hdsi, &PLLInit) != HAL_OK)
  {
    Error_Handler();
  }
  HostTimeouts.TimeoutCkdiv = 1;
  HostTimeouts.HighSpeedTransmissionTimeout = 0;
  HostTimeouts.LowPowerReceptionTimeout = 0;
  HostTimeouts.HighSpeedReadTimeout = 0;
  HostTimeouts.LowPowerReadTimeout = 0;
  HostTimeouts.HighSpeedWriteTimeout = 0;
  HostTimeouts.HighSpeedWritePrespMode = DSI_HS_PM_DISABLE;
  HostTimeouts.LowPowerWriteTimeout = 0;
  HostTimeouts.BTATimeout = 0;
  if (HAL_DSI_ConfigHostTimeouts(&hdsi, &HostTimeouts) != HAL_OK)
  {
    Error_Handler();
  }
  PhyTimings.ClockLaneHS2LPTime = 28;
  PhyTimings.ClockLaneLP2HSTime = 33;
  PhyTimings.DataLaneHS2LPTime = 15;
  PhyTimings.DataLaneLP2HSTime = 25;
  PhyTimings.DataLaneMaxReadTime = 0;
  PhyTimings.StopWaitTime = 0;
  if (HAL_DSI_ConfigPhyTimer(&hdsi, &PhyTimings) != HAL_OK)
  {
    Error_Handler();
  }
  if (HAL_DSI_SetLowPowerRXFilter(&hdsi, 10000) != HAL_OK)
  {
    Error_Handler();
  }
  if (HAL_DSI_ConfigErrorMonitor(&hdsi, HAL_DSI_ERROR_OVF) != HAL_OK)
  {
    Error_Handler();
  }
  VidCfg.VirtualChannelID = 0;
  VidCfg.ColorCoding = DSI_RGB565;
  VidCfg.LooselyPacked = DSI_LOOSELY_PACKED_DISABLE;
  VidCfg.Mode = DSI_VID_MODE_BURST;
  VidCfg.PacketSize = 280;
  VidCfg.NumberOfChunks = 0;
  VidCfg.NullPacketSize = 0;
  VidCfg.HSPolarity = DSI_HSYNC_ACTIVE_LOW;
  VidCfg.VSPolarity = DSI_VSYNC_ACTIVE_LOW;
  VidCfg.DEPolarity = DSI_DATA_ENABLE_ACTIVE_HIGH;
  VidCfg.HorizontalSyncActive = 38;
  VidCfg.HorizontalBackPorch = 63;
  VidCfg.HorizontalLine = 772;
  VidCfg.VerticalSyncActive = 6;
  VidCfg.VerticalBackPorch = 10;
  VidCfg.VerticalFrontPorch = 12;
  VidCfg.VerticalActive = 1424;
  VidCfg.LPCommandEnable = DSI_LP_COMMAND_ENABLE;
  VidCfg.LPLargestPacketSize = 16;
  VidCfg.LPVACTLargestPacketSize = 0;
  VidCfg.LPHorizontalFrontPorchEnable = DSI_LP_HFP_ENABLE;
  VidCfg.LPHorizontalBackPorchEnable = DSI_LP_HBP_ENABLE;
  VidCfg.LPVerticalActiveEnable = DSI_LP_VACT_ENABLE;
  VidCfg.LPVerticalFrontPorchEnable = DSI_LP_VFP_ENABLE;
  VidCfg.LPVerticalBackPorchEnable = DSI_LP_VBP_ENABLE;
  VidCfg.LPVerticalSyncActiveEnable = DSI_LP_VSYNC_ENABLE;
  VidCfg.FrameBTAAcknowledgeEnable = DSI_FBTAA_ENABLE;
  if (HAL_DSI_ConfigVideoMode(&hdsi, &VidCfg) != HAL_OK)
  {
    Error_Handler();
  }
  if (HAL_DSI_SetGenericVCID(&hdsi, 0) != HAL_OK)
  {
    Error_Handler();
  }

}

static void MX_I2C1_Init(void)
{

  hi2c1.Instance = I2C1;
  hi2c1.Init.Timing = 0x109035B7;
  hi2c1.Init.OwnAddress1 = 0;
  hi2c1.Init.AddressingMode = I2C_ADDRESSINGMODE_7BIT;
  hi2c1.Init.DualAddressMode = I2C_DUALADDRESS_DISABLE;
  hi2c1.Init.OwnAddress2 = 0;
  hi2c1.Init.OwnAddress2Masks = I2C_OA2_NOMASK;
  hi2c1.Init.GeneralCallMode = I2C_GENERALCALL_DISABLE;
  hi2c1.Init.NoStretchMode = I2C_NOSTRETCH_DISABLE;
  if (HAL_I2C_Init(&hi2c1) != HAL_OK)
  {
    Error_Handler();
  }

  /** Configure Analogue filter
  */
  if (HAL_I2CEx_ConfigAnalogFilter(&hi2c1, I2C_ANALOGFILTER_ENABLE) != HAL_OK)
  {
    Error_Handler();
  }

  /** Configure Digital filter
  */
  if (HAL_I2CEx_ConfigDigitalFilter(&hi2c1, 0) != HAL_OK)
  {
    Error_Handler();
  }

}

static void MX_LTDC_Init(void)
{

  LTDC_LayerCfgTypeDef pLayerCfg = {0};

  hltdc.Instance = LTDC;
  hltdc.Init.HSPolarity = LTDC_HSPOLARITY_AL;
  hltdc.Init.VSPolarity = LTDC_VSPOLARITY_AL;
  hltdc.Init.DEPolarity = LTDC_DEPOLARITY_AL;
  hltdc.Init.PCPolarity = LTDC_PCPOLARITY_IPC;
  hltdc.Init.HorizontalSync = 23;
  hltdc.Init.VerticalSync = 5;
  hltdc.Init.AccumulatedHBP = 63;
  hltdc.Init.AccumulatedVBP = 15;
  hltdc.Init.AccumulatedActiveW = 343;
  hltdc.Init.AccumulatedActiveH = 1439;
  hltdc.Init.TotalWidth = 493;
  hltdc.Init.TotalHeigh = 1451;
  hltdc.Init.Backcolor.Blue = 0;
  hltdc.Init.Backcolor.Green = 0;
  hltdc.Init.Backcolor.Red = 0;
  if (HAL_LTDC_Init(&hltdc) != HAL_OK)
  {
    Error_Handler();
  }
  pLayerCfg.WindowX0 = 0;
  pLayerCfg.WindowX1 = 280;
  pLayerCfg.WindowY0 = 0;
  pLayerCfg.WindowY1 = 1424;
  pLayerCfg.PixelFormat = LTDC_PIXEL_FORMAT_RGB565;
  pLayerCfg.Alpha = 255;
  pLayerCfg.Alpha0 = 0;
  pLayerCfg.BlendingFactor1 = LTDC_BLENDING_FACTOR1_CA;
  pLayerCfg.BlendingFactor2 = LTDC_BLENDING_FACTOR2_CA;
  pLayerCfg.FBStartAdress = 0xC0000000;
  pLayerCfg.ImageWidth = 280;
  pLayerCfg.ImageHeight = 1424;
  pLayerCfg.Backcolor.Blue = 255;
  pLayerCfg.Backcolor.Green = 255;
  pLayerCfg.Backcolor.Red = 255;
  if (HAL_LTDC_ConfigLayer(&hltdc, &pLayerCfg, 0) != HAL_OK)
  {
    Error_Handler();
  }

}

static void MX_QUADSPI_Init(void)
{

  /* QUADSPI parameter configuration*/
  hqspi.Instance = QUADSPI;
  hqspi.Init.ClockPrescaler = 2;
  hqspi.Init.FifoThreshold = 4;
  hqspi.Init.SampleShifting = QSPI_SAMPLE_SHIFTING_HALFCYCLE;
  hqspi.Init.FlashSize = 23;
  hqspi.Init.ChipSelectHighTime = QSPI_CS_HIGH_TIME_2_CYCLE;
  hqspi.Init.ClockMode = QSPI_CLOCK_MODE_0;
  hqspi.Init.FlashID = QSPI_FLASH_ID_1;
  hqspi.Init.DualFlash = QSPI_DUALFLASH_DISABLE;
  if (HAL_QSPI_Init(&hqspi) != HAL_OK)
  {
    Error_Handler();
  }
  /* USER CODE BEGIN QUADSPI_Init 2 */
  exflash_init( );
  /* USER CODE END QUADSPI_Init 2 */

}

static void MX_RTC_Init(void)
{

  RTC_TimeTypeDef sTime = {0};
  RTC_DateTypeDef sDate = {0};

  /** Initialize RTC Only
  */
  hrtc.Instance = RTC;
  hrtc.Init.HourFormat = RTC_HOURFORMAT_24;
  hrtc.Init.AsynchPrediv = 127;
  hrtc.Init.SynchPrediv = 255;
  hrtc.Init.OutPut = RTC_OUTPUT_DISABLE;
  hrtc.Init.OutPutPolarity = RTC_OUTPUT_POLARITY_HIGH;
  hrtc.Init.OutPutType = RTC_OUTPUT_TYPE_OPENDRAIN;
  if (HAL_RTC_Init(&hrtc) != HAL_OK)
  {
    Error_Handler();
  }

  /* USER CODE BEGIN Check_RTC_BKUP */
  if( HAL_RTCEx_BKUPRead(&hrtc, RTC_BKP_DR0) == 0x32F2 )
  {
	  return;
  }
  /* USER CODE END Check_RTC_BKUP */

  /** Initialize RTC and set the Time and Date
  */
  sTime.Hours = 0;
  sTime.Minutes = 0;
  sTime.Seconds = 0;
  sTime.DayLightSaving = RTC_DAYLIGHTSAVING_NONE;
  sTime.StoreOperation = RTC_STOREOPERATION_RESET;
  if (HAL_RTC_SetTime(&hrtc, &sTime, RTC_FORMAT_BIN) != HAL_OK)
  {
    Error_Handler();
  }
  sDate.WeekDay = RTC_WEEKDAY_MONDAY;
  sDate.Month = RTC_MONTH_JANUARY;
  sDate.Date = 1;
  sDate.Year = 24;

  if (HAL_RTC_SetDate(&hrtc, &sDate, RTC_FORMAT_BIN) != HAL_OK)
  {
    Error_Handler();
  }
  /* USER CODE BEGIN RTC_Init 2 */
  HAL_RTCEx_BKUPWrite( &hrtc, RTC_BKP_DR0, 0x32F2 );
  /* USER CODE END RTC_Init 2 */

}

static void MX_SDMMC1_SD_Init(void)
{

  hsd1.Instance = SDMMC1;
  hsd1.Init.ClockEdge = SDMMC_CLOCK_EDGE_RISING;
  hsd1.Init.ClockBypass = SDMMC_CLOCK_BYPASS_DISABLE;
  hsd1.Init.ClockPowerSave = SDMMC_CLOCK_POWER_SAVE_DISABLE;
  hsd1.Init.BusWide = SDMMC_BUS_WIDE_1B;
  hsd1.Init.HardwareFlowControl = SDMMC_HARDWARE_FLOW_CONTROL_DISABLE;
  hsd1.Init.ClockDiv = 0;

}

static void MX_TIM3_Init(void)
{

  TIM_ClockConfigTypeDef sClockSourceConfig = {0};
  TIM_MasterConfigTypeDef sMasterConfig = {0};
  TIM_OC_InitTypeDef sConfigOC = {0};

  htim3.Instance = TIM3;
  htim3.Init.Prescaler = 100-1;
  htim3.Init.CounterMode = TIM_COUNTERMODE_UP;
  htim3.Init.Period = 100-1;
  htim3.Init.ClockDivision = TIM_CLOCKDIVISION_DIV1;
  htim3.Init.AutoReloadPreload = TIM_AUTORELOAD_PRELOAD_DISABLE;
  if (HAL_TIM_Base_Init(&htim3) != HAL_OK)
  {
    Error_Handler();
  }
  sClockSourceConfig.ClockSource = TIM_CLOCKSOURCE_INTERNAL;
  if (HAL_TIM_ConfigClockSource(&htim3, &sClockSourceConfig) != HAL_OK)
  {
    Error_Handler();
  }
  if (HAL_TIM_PWM_Init(&htim3) != HAL_OK)
  {
    Error_Handler();
  }
  sMasterConfig.MasterOutputTrigger = TIM_TRGO_RESET;
  sMasterConfig.MasterSlaveMode = TIM_MASTERSLAVEMODE_DISABLE;
  if (HAL_TIMEx_MasterConfigSynchronization(&htim3, &sMasterConfig) != HAL_OK)
  {
    Error_Handler();
  }
  sConfigOC.OCMode = TIM_OCMODE_PWM1;
  sConfigOC.Pulse = 0;
  sConfigOC.OCPolarity = TIM_OCPOLARITY_LOW;
  sConfigOC.OCFastMode = TIM_OCFAST_DISABLE;
  if (HAL_TIM_PWM_ConfigChannel(&htim3, &sConfigOC, TIM_CHANNEL_3) != HAL_OK)
  {
    Error_Handler();
  }
  HAL_TIM_MspPostInit(&htim3);

}

static void MX_USART6_UART_Init(void)
{

  huart6.Instance = USART6;
  huart6.Init.BaudRate = 115200;
  huart6.Init.WordLength = UART_WORDLENGTH_8B;
  huart6.Init.StopBits = UART_STOPBITS_1;
  huart6.Init.Parity = UART_PARITY_NONE;
  huart6.Init.Mode = UART_MODE_TX_RX;
  huart6.Init.HwFlowCtl = UART_HWCONTROL_NONE;
  huart6.Init.OverSampling = UART_OVERSAMPLING_16;
  huart6.Init.OneBitSampling = UART_ONE_BIT_SAMPLE_DISABLE;
  huart6.AdvancedInit.AdvFeatureInit = UART_ADVFEATURE_NO_INIT;
  if (HAL_UART_Init(&huart6) != HAL_OK)
  {
    Error_Handler();
  }
  /* USER CODE BEGIN USART6_Init 2 */
  HAL_UART_Abort(&huart6);
  /* USER CODE END USART6_Init 2 */

}

static void MX_DMA_Init(void)
{

  /* DMA controller clock enable */
  __HAL_RCC_DMA2_CLK_ENABLE();

  /* DMA interrupt init */
  /* DMA2_Stream3_IRQn interrupt configuration */
  HAL_NVIC_SetPriority(DMA2_Stream3_IRQn, 5, 0);
  HAL_NVIC_EnableIRQ(DMA2_Stream3_IRQn);
  /* DMA2_Stream6_IRQn interrupt configuration */
  HAL_NVIC_SetPriority(DMA2_Stream6_IRQn, 5, 0);
  HAL_NVIC_EnableIRQ(DMA2_Stream6_IRQn);

}

/* FMC initialization function */
static void MX_FMC_Init(void)
{

  FMC_SDRAM_TimingTypeDef SdramTiming = {0};

  /** Perform the SDRAM1 memory initialization sequence
  */
  hsdram1.Instance = FMC_SDRAM_DEVICE;
  /* hsdram1.Init */
  hsdram1.Init.SDBank = FMC_SDRAM_BANK1;
  hsdram1.Init.ColumnBitsNumber = FMC_SDRAM_COLUMN_BITS_NUM_8;
  hsdram1.Init.RowBitsNumber = FMC_SDRAM_ROW_BITS_NUM_12;
  hsdram1.Init.MemoryDataWidth = FMC_SDRAM_MEM_BUS_WIDTH_32;
  hsdram1.Init.InternalBankNumber = FMC_SDRAM_INTERN_BANKS_NUM_4;
  hsdram1.Init.CASLatency = FMC_SDRAM_CAS_LATENCY_2;
  hsdram1.Init.WriteProtection = FMC_SDRAM_WRITE_PROTECTION_DISABLE;
  hsdram1.Init.SDClockPeriod = FMC_SDRAM_CLOCK_PERIOD_2;
  hsdram1.Init.ReadBurst = FMC_SDRAM_RBURST_ENABLE;
  hsdram1.Init.ReadPipeDelay = FMC_SDRAM_RPIPE_DELAY_0;
  /* SdramTiming */
  SdramTiming.LoadToActiveDelay = 2;
  SdramTiming.ExitSelfRefreshDelay = 8;
  SdramTiming.SelfRefreshTime = 5;
  SdramTiming.RowCycleDelay = 6;
  SdramTiming.WriteRecoveryTime = 4;
  SdramTiming.RPDelay = 2;
  SdramTiming.RCDDelay = 2;

  if (HAL_SDRAM_Init(&hsdram1, &SdramTiming) != HAL_OK)
  {
    Error_Handler( );
  }

  /* USER CODE BEGIN FMC_Init 2 */
  MX_SDRAM_InitEx( );
  /* USER CODE END FMC_Init 2 */
}

static void MX_GPIO_Init(void)
{
  GPIO_InitTypeDef GPIO_InitStruct = {0};

  /* GPIO Ports Clock Enable */
  __HAL_RCC_GPIOE_CLK_ENABLE();
  __HAL_RCC_GPIOC_CLK_ENABLE();
  __HAL_RCC_GPIOI_CLK_ENABLE();
  __HAL_RCC_GPIOF_CLK_ENABLE();
  __HAL_RCC_GPIOH_CLK_ENABLE();
  __HAL_RCC_GPIOB_CLK_ENABLE();
  __HAL_RCC_GPIOG_CLK_ENABLE();
  __HAL_RCC_GPIOD_CLK_ENABLE();
  __HAL_RCC_GPIOA_CLK_ENABLE();

  /*Configure GPIO pin Output Level */
  HAL_GPIO_WritePin(LCD_BL_CTRL_GPIO_Port, LCD_BL_CTRL_Pin, GPIO_PIN_RESET);

  /*Configure GPIO pin Output Level */
  HAL_GPIO_WritePin(GPIO_OUT_BEEP_GPIO_Port, GPIO_OUT_BEEP_Pin, GPIO_PIN_RESET);

  /*Configure GPIO pin Output Level */
  HAL_GPIO_WritePin(CTP_RST_GPIO_Port, CTP_RST_Pin, GPIO_PIN_RESET);

  /*Configure GPIO pin : LCD_BL_CTRL_Pin */
  GPIO_InitStruct.Pin = LCD_BL_CTRL_Pin;
  GPIO_InitStruct.Mode = GPIO_MODE_OUTPUT_PP;
  GPIO_InitStruct.Pull = GPIO_NOPULL;
  GPIO_InitStruct.Speed = GPIO_SPEED_FREQ_VERY_HIGH;
  HAL_GPIO_Init(LCD_BL_CTRL_GPIO_Port, &GPIO_InitStruct);

  /*Configure GPIO pin : SD_CD_Pin */
  GPIO_InitStruct.Pin = SD_CD_Pin;
  GPIO_InitStruct.Mode = GPIO_MODE_INPUT;
  GPIO_InitStruct.Pull = GPIO_NOPULL;
  HAL_GPIO_Init(SD_CD_GPIO_Port, &GPIO_InitStruct);

  /*Configure GPIO pin : GPIO_OUT_BEEP_Pin */
  GPIO_InitStruct.Pin = GPIO_OUT_BEEP_Pin;
  GPIO_InitStruct.Mode = GPIO_MODE_OUTPUT_PP;
  GPIO_InitStruct.Pull = GPIO_NOPULL;
  GPIO_InitStruct.Speed = GPIO_SPEED_FREQ_VERY_HIGH;
  HAL_GPIO_Init(GPIO_OUT_BEEP_GPIO_Port, &GPIO_InitStruct);

  /*Configure GPIO pin : CTP_INT_Pin */
  GPIO_InitStruct.Pin = CTP_INT_Pin;
  GPIO_InitStruct.Mode = GPIO_MODE_IT_FALLING;
  GPIO_InitStruct.Pull = GPIO_NOPULL;
  HAL_GPIO_Init(CTP_INT_GPIO_Port, &GPIO_InitStruct);

  /*Configure GPIO pin : CTP_RST_Pin */
  GPIO_InitStruct.Pin = CTP_RST_Pin;
  GPIO_InitStruct.Mode = GPIO_MODE_OUTPUT_PP;
  GPIO_InitStruct.Pull = GPIO_NOPULL;
  GPIO_InitStruct.Speed = GPIO_SPEED_FREQ_LOW;
  HAL_GPIO_Init(CTP_RST_GPIO_Port, &GPIO_InitStruct);

  /* EXTI interrupt init*/
  HAL_NVIC_SetPriority(EXTI3_IRQn, 5, 0);
  HAL_NVIC_EnableIRQ(EXTI3_IRQn);

}

/* USER CODE BEGIN 4 */
static void MX_SDRAM_InitEx ( void )
{

  /* For SDRAM initial */
  /****************************************************************/
  // In datasheet, Refresh Cycle Time(4096) = 64ms
  // Freq = 108M Hz
  // REFRESH_COUNT = ( 64m / 4096 ) * 108M - 20 = 1667.5
  // REFRESH_COUNT = ( 64mSec / 4096 ) * 10nSec (100MHz) - 20 =  1542
  /****************************************************************/
  #define REFRESH_COUNT        1540
  #define SDRAM_TIMEOUT                            ((uint32_t)0xFFFF)
  #define SDRAM_MODEREG_BURST_LENGTH_1             ((uint16_t)0x0000)
  #define SDRAM_MODEREG_BURST_LENGTH_2             ((uint16_t)0x0001)
  #define SDRAM_MODEREG_BURST_LENGTH_4             ((uint16_t)0x0002)
  #define SDRAM_MODEREG_BURST_LENGTH_8             ((uint16_t)0x0004)
  #define SDRAM_MODEREG_BURST_TYPE_SEQUENTIAL      ((uint16_t)0x0000)
  #define SDRAM_MODEREG_BURST_TYPE_INTERLEAVED     ((uint16_t)0x0008)
  #define SDRAM_MODEREG_CAS_LATENCY_2              ((uint16_t)0x0020)
  #define SDRAM_MODEREG_CAS_LATENCY_3              ((uint16_t)0x0030)
  #define SDRAM_MODEREG_OPERATING_MODE_STANDARD    ((uint16_t)0x0000)
  #define SDRAM_MODEREG_WRITEBURST_MODE_PROGRAMMED ((uint16_t)0x0000)
  #define SDRAM_MODEREG_WRITEBURST_MODE_SINGLE     ((uint16_t)0x0200)

  __IO uint32_t tmpmrd = 0;
  FMC_SDRAM_CommandTypeDef Command;

  /* Step 1: Configure a clock configuration enable command */
  Command.CommandMode            = FMC_SDRAM_CMD_CLK_ENABLE;
  Command.CommandTarget          = FMC_SDRAM_CMD_TARGET_BANK1;
  Command.AutoRefreshNumber      = 1;
  Command.ModeRegisterDefinition = 0;

  /* Send the command */
  HAL_SDRAM_SendCommand(&hsdram1, &Command, SDRAM_TIMEOUT);

  /* Step 2: Insert 100 us minimum delay */
  /* Inserted delay is equal to 1 ms due to systick time base unit (ms) */
  HAL_Delay(1);

  /* Step 3: Configure a PALL (precharge all) command */
  Command.CommandMode            = FMC_SDRAM_CMD_PALL;
  Command.CommandTarget          = FMC_SDRAM_CMD_TARGET_BANK1;
  Command.AutoRefreshNumber      = 1;
  Command.ModeRegisterDefinition = 0;

  /* Send the command */
  HAL_SDRAM_SendCommand(&hsdram1, &Command, SDRAM_TIMEOUT);

  /* Step 4: Configure an Auto Refresh command */
  Command.CommandMode            = FMC_SDRAM_CMD_AUTOREFRESH_MODE;
  Command.CommandTarget          = FMC_SDRAM_CMD_TARGET_BANK1;
  Command.AutoRefreshNumber      = 8;
  Command.ModeRegisterDefinition = 0;

  /* Send the command */
  HAL_SDRAM_SendCommand(&hsdram1, &Command, SDRAM_TIMEOUT);

  /* Step 5: Program the external memory mode register */
  tmpmrd = (uint32_t)SDRAM_MODEREG_BURST_LENGTH_1          |\
                     SDRAM_MODEREG_BURST_TYPE_SEQUENTIAL   |\
					           SDRAM_MODEREG_CAS_LATENCY_2           |\
                     SDRAM_MODEREG_OPERATING_MODE_STANDARD |\
                     SDRAM_MODEREG_WRITEBURST_MODE_SINGLE;

  Command.CommandMode            = FMC_SDRAM_CMD_LOAD_MODE;
  Command.CommandTarget          = FMC_SDRAM_CMD_TARGET_BANK1;
  Command.AutoRefreshNumber      = 1;
  Command.ModeRegisterDefinition = tmpmrd;

  /* Send the command */
  HAL_SDRAM_SendCommand(&hsdram1, &Command, SDRAM_TIMEOUT);

  /* Step 6: Set the refresh rate counter */
  /* Set the device refresh rate */
  HAL_SDRAM_ProgramRefreshRate(&hsdram1, REFRESH_COUNT);
}

void set_clock_to_RTC ( calendar_t calendar )
{
	RTC_TimeTypeDef sTime = { 0 };
	RTC_DateTypeDef sDate = { 0 };

	sTime.Hours = calendar.map.Hours;
	sTime.Minutes = calendar.map.Minutes;
	sTime.Seconds = calendar.map.Seconds;
	sTime.DayLightSaving = RTC_DAYLIGHTSAVING_NONE;
	sTime.StoreOperation = RTC_STOREOPERATION_RESET;
	if( HAL_RTC_SetTime(&hrtc, &sTime, RTC_FORMAT_BIN) != HAL_OK )
	{

	}
	sDate.WeekDay = calendar.map.WeekDay;
	sDate.Month = calendar.map.Month;
	sDate.Date = calendar.map.Date;
	sDate.Year = calendar.map.Year;

	if( HAL_RTC_SetDate(&hrtc, &sDate, RTC_FORMAT_BIN) != HAL_OK )
	{

	}

	HAL_RTCEx_BKUPWrite( &hrtc, RTC_BKP_DR1, 0x32F2 );
}

void get_clock_from_RTC ( calendar_t *calendar )
{
	RTC_TimeTypeDef sTime = { 0 };
	RTC_DateTypeDef sDate = { 0 };

	/* Get the RTC current Time */
	HAL_RTC_GetTime( &hrtc, &sTime, RTC_FORMAT_BIN );
	/* Get the RTC current Date */
	HAL_RTC_GetDate( &hrtc, &sDate, RTC_FORMAT_BIN );

	calendar->map.Hours = sTime.Hours;
	calendar->map.Minutes = sTime.Minutes;
	calendar->map.Seconds = sTime.Seconds;

	calendar->map.WeekDay = sDate.WeekDay;
	calendar->map.Month = sDate.Month;
	calendar->map.Date = sDate.Date;
	calendar->map.Year = sDate.Year;
}

void HAL_GPIO_EXTI_Callback(uint16_t GPIO_Pin)
{
	uint8_t Buf1[ 10 ];
  if(GPIO_Pin == GPIO_PIN_3)
  {
		if(HAL_I2C_Mem_Read(&hi2c1,0xBB,0x814E,I2C_MEMADD_SIZE_16BIT,&Buf1[0],1,10) == HAL_OK)
		{
			Touch.Status = Buf1[0] >> 7;
			Touch.Number  = Buf1[0] & 0x0F;
			Buf1[0] = 0;
			HAL_I2C_Mem_Write(&hi2c1,0xBA,0x814E,I2C_MEMADD_SIZE_16BIT,&Buf1[0],1,10);
		}
  }
}

/**
  * @brief  Line Event callback.
  * @param  hltdc: pointer to a LTDC_HandleTypeDef structure that contains
  *                the configuration information for the LTDC.
  * @retval None
  */

/* USER CODE END 4 */

void display_debugTask(void *argument)
{
  for(;;)
  {
    osDelay(1);
  }
}

void StartTouchgfxTask(void *argument)
{
  /* USER CODE BEGIN StartTouchgfxTask */
  MX_TouchGFX_Process( );

  /* Infinite loop */
  for(;;)
  {
    osDelay(1);
  }
  /* USER CODE END StartTouchgfxTask */
}

/* MPU Configuration */

void MPU_Config(void)
{
  MPU_Region_InitTypeDef MPU_InitStruct = {0};

  /* Disables the MPU */
  HAL_MPU_Disable();

  /** Initializes and configures the Region and the memory to be protected
  */
  MPU_InitStruct.Enable = MPU_REGION_ENABLE;
  MPU_InitStruct.Number = MPU_REGION_NUMBER0;
  MPU_InitStruct.BaseAddress = 0xC0000000;
  MPU_InitStruct.Size = MPU_REGION_SIZE_16MB;
  MPU_InitStruct.SubRegionDisable = 0x0;
  MPU_InitStruct.TypeExtField = MPU_TEX_LEVEL0;
  MPU_InitStruct.AccessPermission = MPU_REGION_FULL_ACCESS;
  MPU_InitStruct.DisableExec = MPU_INSTRUCTION_ACCESS_ENABLE;
  MPU_InitStruct.IsShareable = MPU_ACCESS_SHAREABLE;
  MPU_InitStruct.IsCacheable = MPU_ACCESS_CACHEABLE;
  MPU_InitStruct.IsBufferable = MPU_ACCESS_NOT_BUFFERABLE;

  HAL_MPU_ConfigRegion(&MPU_InitStruct);

  /** Initializes and configures the Region and the memory to be protected
  */
  MPU_InitStruct.Number = MPU_REGION_NUMBER1;
  MPU_InitStruct.BaseAddress = 0x90000000;
  MPU_InitStruct.Size = MPU_REGION_SIZE_256MB;
  MPU_InitStruct.AccessPermission = MPU_REGION_NO_ACCESS;
  MPU_InitStruct.DisableExec = MPU_INSTRUCTION_ACCESS_DISABLE;
  MPU_InitStruct.IsShareable = MPU_ACCESS_NOT_SHAREABLE;
  MPU_InitStruct.IsCacheable = MPU_ACCESS_NOT_CACHEABLE;

  HAL_MPU_ConfigRegion(&MPU_InitStruct);

  /** Initializes and configures the Region and the memory to be protected
  */
  MPU_InitStruct.Number = MPU_REGION_NUMBER2;
  MPU_InitStruct.Size = MPU_REGION_SIZE_16MB;
  MPU_InitStruct.AccessPermission = MPU_REGION_PRIV_RO;
  MPU_InitStruct.IsCacheable = MPU_ACCESS_CACHEABLE;

  HAL_MPU_ConfigRegion(&MPU_InitStruct);
  /* Enables the MPU */
  HAL_MPU_Enable(MPU_PRIVILEGED_DEFAULT);

}

void HAL_TIM_PeriodElapsedCallback(TIM_HandleTypeDef *htim)
{
  if (htim->Instance == TIM6) {
    HAL_IncTick();
  }
}

void Error_Handler(void)
{
  __disable_irq();
  while (1)
  {
  }
}
